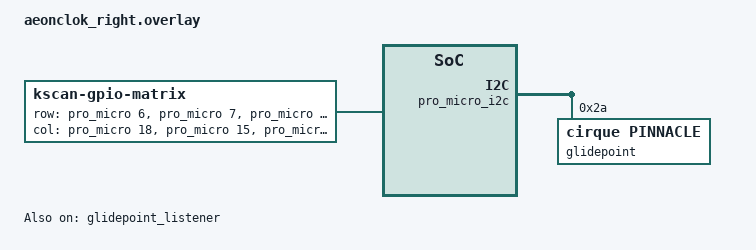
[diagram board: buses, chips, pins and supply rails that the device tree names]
#include "aeonclok.dtsi"

/ {
    chosen {
        zmk,kscan = &kscan;
    };

    kscan: kscan {
        compatible = "zmk,kscan-gpio-matrix";
        wakeup-source;

        diode-direction = "row2col";

        row-gpios
            = <&pro_micro 6 GPIO_ACTIVE_HIGH>
            , <&pro_micro 7 GPIO_ACTIVE_HIGH>
            , <&pro_micro 8 GPIO_ACTIVE_HIGH>
            , <&pro_micro 9 GPIO_ACTIVE_HIGH>
            ;

        col-gpios
            = <&pro_micro 18 (GPIO_PULL_DOWN | GPIO_ACTIVE_HIGH)>
            , <&pro_micro 15  (GPIO_PULL_DOWN | GPIO_ACTIVE_HIGH)>
            , <&pro_micro 14  (GPIO_PULL_DOWN | GPIO_ACTIVE_HIGH)>
            , <&pro_micro 16  (GPIO_PULL_DOWN | GPIO_ACTIVE_HIGH)>
            , <&pro_micro 10  (GPIO_PULL_DOWN | GPIO_ACTIVE_HIGH)>
            ;
    };
};

&default_transform {
    col-offset = <5>;
};

&pro_micro_i2c {
    status = "okay";
    glidepoint: glidepoint@2a {
        compatible = "cirque,pinnacle";
        reg = <0x2a>;
        status = "okay";
    };
};

// Overrides for the input listener node
&glidepoint_listener {
    status = "okay";
    device = <&glidepoint>;
};
